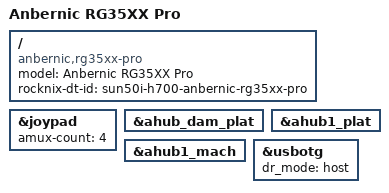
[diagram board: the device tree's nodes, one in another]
// SPDX-License-Identifier: (GPL-2.0-only OR BSD-2-Clause)
/*
 * Copyright (C) 2024 Ryan Walklin <ryan@testtoast.com>.
 * Copyright (C) 2024 Chris Morgan <macroalpha82@gmail.com>.
 */

#include "sun50i-h700-anbernic-rg35xx-plus.dts"

/ {
	model = "Anbernic RG35XX Pro";
	compatible = "anbernic,rg35xx-pro", "allwinner,sun50i-h700";
	rocknix-dt-id = "sun50i-h700-anbernic-rg35xx-pro";
};

&joypad {
	amux-count = <4>;
};

/*
 * HDMI audio via Allwinner AHUB → dw-hdmi-i2s-audio. AHUB nodes are
 * added to sun50i-h616.dtsi by Armbian patches 0224-0701 / 0225-0702
 * with status="disabled"; this enables them for RG35XX Pro. Mirrors
 * what 0701 does for sun50i-h616-orangepi-zero.dtsi.
 */
&ahub_dam_plat {
	status = "okay";
};

&ahub1_plat {
	status = "okay";
};

&ahub1_mach {
	status = "okay";
};

/* USB-C host mode: force host so MUSB enables VBUS without CC-pin ID detection */
&usbotg {
	dr_mode = "host";
};
